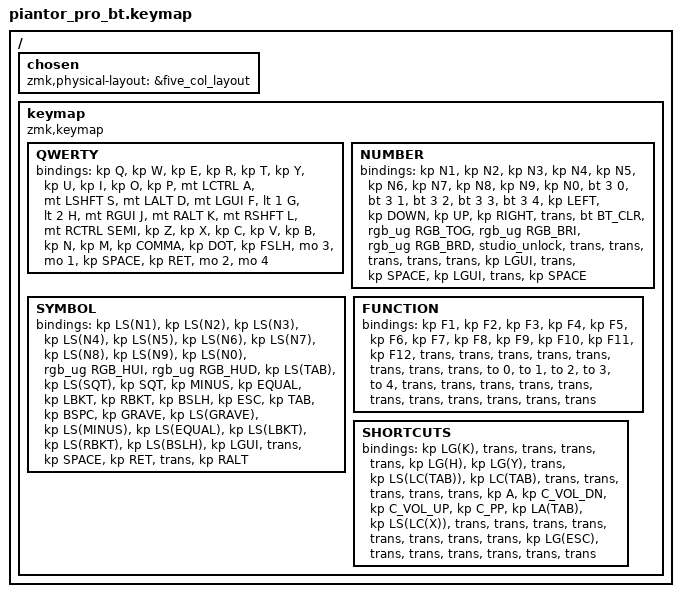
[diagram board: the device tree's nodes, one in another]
#include <behaviors.dtsi>
#include <dt-bindings/zmk/bt.h>
#include <dt-bindings/zmk/keys.h>
#include <dt-bindings/zmk/rgb.h>

/ {
    chosen {
        zmk,physical-layout = &five_col_layout;
    };
};

/ {
    keymap {
        compatible = "zmk,keymap";

        QWERTY {
            bindings = <
  &kp Q  &kp W  &kp E  &kp R  &kp T  &kp Y  &kp U  &kp I  &kp O  &kp P      &mt LCTRL A  &mt LSHFT S  &mt LALT D  &mt LGUI F  &lt 1 G  &lt 2 H  &mt RGUI J  &mt RALT K  &mt RSHFT L  &mt RCTRL SEMI      &kp Z  &kp X  &kp C  &kp V  &kp B  &kp N  &kp M  &kp COMMA  &kp DOT  &kp FSLH    &mo 3  &mo 1  &kp SPACE  &kp RET  &mo 2  &mo 4
            >;
        };

        NUMBER {
            bindings = <
  &kp N1  &kp N2  &kp N3  &kp N4  &kp N5  &kp N6  &kp N7  &kp N8  &kp N9  &kp N0      &bt 3 0  &bt 3 1  &bt 3 2  &bt 3 3  &bt 3 4  &kp LEFT  &kp DOWN  &kp UP  &kp RIGHT  &trans      &bt BT_CLR  &rgb_ug RGB_TOG  &rgb_ug RGB_BRI  &rgb_ug RGB_BRD  &studio_unlock  &trans  &trans  &trans  &trans  &trans    &kp LGUI  &trans  &kp SPACE  &kp LGUI  &trans  &kp SPACE
            >;
        };

        SYMBOL {
            bindings = <
  &kp LS(N1)  &kp LS(N2)  &kp LS(N3)  &kp LS(N4)  &kp LS(N5)  &kp LS(N6)  &kp LS(N7)  &kp LS(N8)  &kp LS(N9)  &kp LS(N0)      &rgb_ug RGB_HUI  &rgb_ug RGB_HUD  &kp LS(TAB)  &kp LS(SQT)  &kp SQT  &kp MINUS  &kp EQUAL  &kp LBKT  &kp RBKT  &kp BSLH      &kp ESC  &kp TAB  &kp BSPC  &kp GRAVE  &kp LS(GRAVE)  &kp LS(MINUS)  &kp LS(EQUAL)  &kp LS(LBKT)  &kp LS(RBKT)  &kp LS(BSLH)    &kp LGUI  &trans  &kp SPACE  &kp RET  &trans  &kp RALT
            >;
        };

        FUNCTION {
            bindings = <
  &kp F1  &kp F2  &kp F3  &kp F4  &kp F5  &kp F6  &kp F7  &kp F8  &kp F9  &kp F10      &kp F11  &kp F12  &trans  &trans  &trans  &trans  &trans  &trans  &trans  &trans      &to 0  &to 1  &to 2  &to 3  &to 4  &trans  &trans  &trans  &trans  &trans    &trans  &trans  &trans  &trans  &trans  &trans
            >;
        };

        SHORTCUTS {
            bindings = <
  &kp LG(K)  &trans  &trans  &trans  &trans  &kp LG(H)  &kp LG(Y)  &trans  &kp LS(LC(TAB))  &kp LC(TAB)      &trans  &trans  &trans  &trans  &trans  &kp A  &kp C_VOL_DN  &kp C_VOL_UP  &kp C_PP  &kp LA(TAB)      &kp LS(LC(X))  &trans  &trans  &trans  &trans  &trans  &trans  &trans  &trans  &kp LG(ESC)    &trans  &trans  &trans  &trans  &trans  &trans
            >;
        };
    };
};
